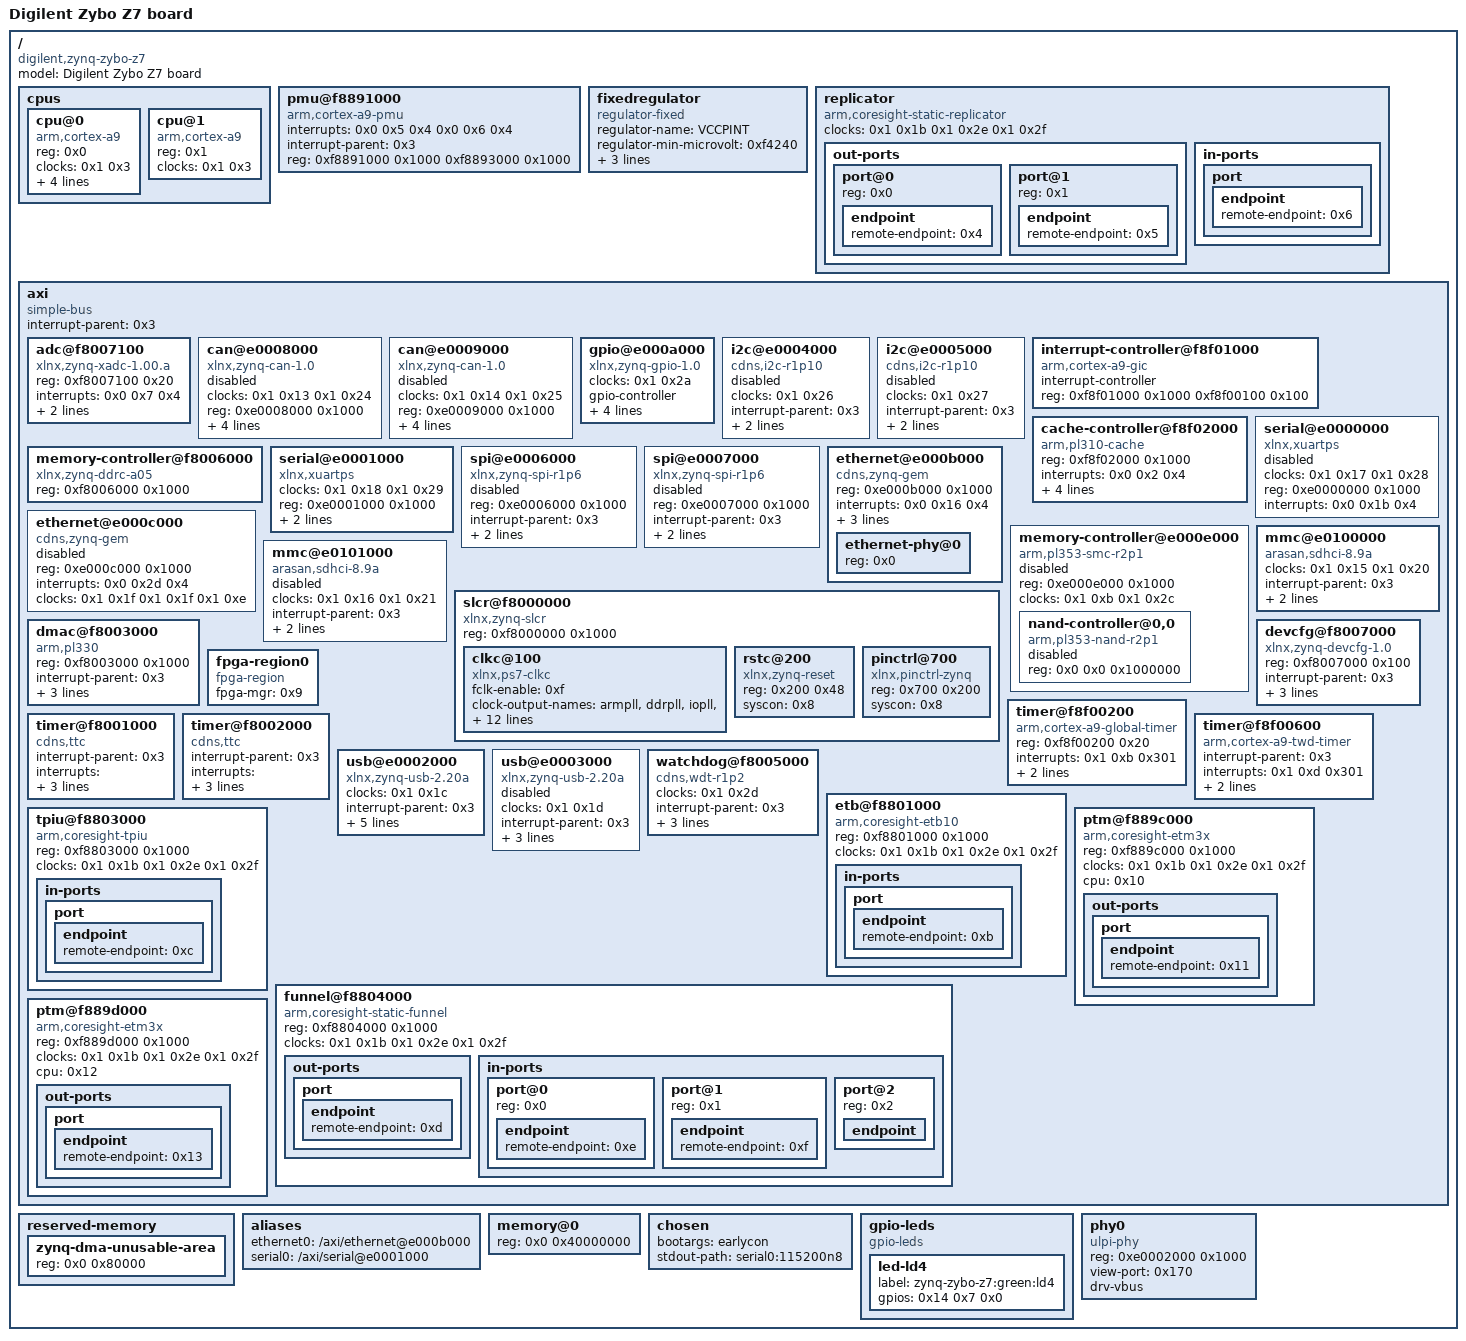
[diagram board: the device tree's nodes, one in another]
/dts-v1/;

/ {
	#address-cells = <0x1>;
	#size-cells = <0x1>;
	compatible = "digilent,zynq-zybo-z7", "xlnx,zynq-7000";
	model = "Digilent Zybo Z7 board";

	cpus {
		#address-cells = <0x1>;
		#size-cells = <0x0>;

		cpu@0 {
			compatible = "arm,cortex-a9";
			device_type = "cpu";
			reg = <0x0>;
			clocks = <0x1 0x3>;
			clock-latency = <0x3e8>;
			cpu0-supply = <0x2>;
			operating-points = <0xa2c2b 0xf4240 0x51616 0xf4240>;
			phandle = <0x10>;
		};

		cpu@1 {
			compatible = "arm,cortex-a9";
			device_type = "cpu";
			reg = <0x1>;
			clocks = <0x1 0x3>;
			phandle = <0x12>;
		};
	};

	pmu@f8891000 {
		compatible = "arm,cortex-a9-pmu";
		interrupts = <0x0 0x5 0x4 0x0 0x6 0x4>;
		interrupt-parent = <0x3>;
		reg = <0xf8891000 0x1000 0xf8893000 0x1000>;
	};

	fixedregulator {
		compatible = "regulator-fixed";
		regulator-name = "VCCPINT";
		regulator-min-microvolt = <0xf4240>;
		regulator-max-microvolt = <0xf4240>;
		regulator-boot-on;
		regulator-always-on;
		phandle = <0x2>;
	};

	replicator {
		compatible = "arm,coresight-static-replicator";
		clocks = <0x1 0x1b 0x1 0x2e 0x1 0x2f>;
		clock-names = "apb_pclk", "dbg_trc", "dbg_apb";

		out-ports {
			#address-cells = <0x1>;
			#size-cells = <0x0>;

			port@0 {
				reg = <0x0>;

				endpoint {
					remote-endpoint = <0x4>;
					phandle = <0xc>;
				};
			};

			port@1 {
				reg = <0x1>;

				endpoint {
					remote-endpoint = <0x5>;
					phandle = <0xb>;
				};
			};
		};

		in-ports {

			port {

				endpoint {
					remote-endpoint = <0x6>;
					phandle = <0xd>;
				};
			};
		};
	};

	axi {
		compatible = "simple-bus";
		#address-cells = <0x1>;
		#size-cells = <0x1>;
		interrupt-parent = <0x3>;
		ranges;
		phandle = <0x15>;

		adc@f8007100 {
			compatible = "xlnx,zynq-xadc-1.00.a";
			reg = <0xf8007100 0x20>;
			interrupts = <0x0 0x7 0x4>;
			interrupt-parent = <0x3>;
			clocks = <0x1 0xc>;
			phandle = <0x16>;
		};

		can@e0008000 {
			compatible = "xlnx,zynq-can-1.0";
			status = "disabled";
			clocks = <0x1 0x13 0x1 0x24>;
			clock-names = "can_clk", "pclk";
			reg = <0xe0008000 0x1000>;
			interrupts = <0x0 0x1c 0x4>;
			interrupt-parent = <0x3>;
			tx-fifo-depth = <0x40>;
			rx-fifo-depth = <0x40>;
			phandle = <0x17>;
		};

		can@e0009000 {
			compatible = "xlnx,zynq-can-1.0";
			status = "disabled";
			clocks = <0x1 0x14 0x1 0x25>;
			clock-names = "can_clk", "pclk";
			reg = <0xe0009000 0x1000>;
			interrupts = <0x0 0x33 0x4>;
			interrupt-parent = <0x3>;
			tx-fifo-depth = <0x40>;
			rx-fifo-depth = <0x40>;
			phandle = <0x18>;
		};

		gpio@e000a000 {
			compatible = "xlnx,zynq-gpio-1.0";
			#gpio-cells = <0x2>;
			clocks = <0x1 0x2a>;
			gpio-controller;
			interrupt-controller;
			#interrupt-cells = <0x2>;
			interrupt-parent = <0x3>;
			interrupts = <0x0 0x14 0x4>;
			reg = <0xe000a000 0x1000>;
			phandle = <0x14>;
		};

		i2c@e0004000 {
			compatible = "cdns,i2c-r1p10";
			status = "disabled";
			clocks = <0x1 0x26>;
			interrupt-parent = <0x3>;
			interrupts = <0x0 0x19 0x4>;
			reg = <0xe0004000 0x1000>;
			#address-cells = <0x1>;
			#size-cells = <0x0>;
			phandle = <0x19>;
		};

		i2c@e0005000 {
			compatible = "cdns,i2c-r1p10";
			status = "disabled";
			clocks = <0x1 0x27>;
			interrupt-parent = <0x3>;
			interrupts = <0x0 0x30 0x4>;
			reg = <0xe0005000 0x1000>;
			#address-cells = <0x1>;
			#size-cells = <0x0>;
			phandle = <0x1a>;
		};

		interrupt-controller@f8f01000 {
			compatible = "arm,cortex-a9-gic";
			#interrupt-cells = <0x3>;
			interrupt-controller;
			reg = <0xf8f01000 0x1000 0xf8f00100 0x100>;
			phandle = <0x3>;
		};

		cache-controller@f8f02000 {
			compatible = "arm,pl310-cache";
			reg = <0xf8f02000 0x1000>;
			interrupts = <0x0 0x2 0x4>;
			arm,data-latency = <0x3 0x2 0x2>;
			arm,tag-latency = <0x2 0x2 0x2>;
			cache-unified;
			cache-level = <0x2>;
			phandle = <0x1b>;
		};

		memory-controller@f8006000 {
			compatible = "xlnx,zynq-ddrc-a05";
			reg = <0xf8006000 0x1000>;
			phandle = <0x1c>;
		};

		serial@e0000000 {
			compatible = "xlnx,xuartps", "cdns,uart-r1p8";
			status = "disabled";
			clocks = <0x1 0x17 0x1 0x28>;
			clock-names = "uart_clk", "pclk";
			reg = <0xe0000000 0x1000>;
			interrupts = <0x0 0x1b 0x4>;
			phandle = <0x1d>;
		};

		serial@e0001000 {
			compatible = "xlnx,xuartps", "cdns,uart-r1p8";
			status = "okay";
			clocks = <0x1 0x18 0x1 0x29>;
			clock-names = "uart_clk", "pclk";
			reg = <0xe0001000 0x1000>;
			interrupts = <0x0 0x32 0x4>;
			clock-frequency = <0x1c2000>;
			phandle = <0x1e>;
		};

		spi@e0006000 {
			compatible = "xlnx,zynq-spi-r1p6";
			reg = <0xe0006000 0x1000>;
			status = "disabled";
			interrupt-parent = <0x3>;
			interrupts = <0x0 0x1a 0x4>;
			clocks = <0x1 0x19 0x1 0x22>;
			clock-names = "ref_clk", "pclk";
			#address-cells = <0x1>;
			#size-cells = <0x0>;
			phandle = <0x1f>;
		};

		spi@e0007000 {
			compatible = "xlnx,zynq-spi-r1p6";
			reg = <0xe0007000 0x1000>;
			status = "disabled";
			interrupt-parent = <0x3>;
			interrupts = <0x0 0x31 0x4>;
			clocks = <0x1 0x1a 0x1 0x23>;
			clock-names = "ref_clk", "pclk";
			#address-cells = <0x1>;
			#size-cells = <0x0>;
			phandle = <0x20>;
		};

		ethernet@e000b000 {
			compatible = "cdns,zynq-gem", "cdns,gem";
			reg = <0xe000b000 0x1000>;
			status = "okay";
			interrupts = <0x0 0x16 0x4>;
			clocks = <0x1 0x1e 0x1 0x1e 0x1 0xd>;
			clock-names = "pclk", "hclk", "tx_clk";
			#address-cells = <0x1>;
			#size-cells = <0x0>;
			phy-mode = "rgmii-id";
			phy-handle = <0x7>;
			phandle = <0x21>;

			ethernet-phy@0 {
				reg = <0x0>;
				device_type = "ethernet-phy";
				phandle = <0x7>;
			};
		};

		ethernet@e000c000 {
			compatible = "cdns,zynq-gem", "cdns,gem";
			reg = <0xe000c000 0x1000>;
			status = "disabled";
			interrupts = <0x0 0x2d 0x4>;
			clocks = <0x1 0x1f 0x1 0x1f 0x1 0xe>;
			clock-names = "pclk", "hclk", "tx_clk";
			#address-cells = <0x1>;
			#size-cells = <0x0>;
			phandle = <0x22>;
		};

		memory-controller@e000e000 {
			compatible = "arm,pl353-smc-r2p1", "arm,primecell";
			reg = <0xe000e000 0x1000>;
			status = "disabled";
			clock-names = "memclk", "apb_pclk";
			clocks = <0x1 0xb 0x1 0x2c>;
			ranges = <0x0 0x0 0xe1000000 0x1000000 0x1 0x0 0xe2000000 0x2000000 0x2 0x0 0xe4000000 0x2000000>;
			#address-cells = <0x2>;
			#size-cells = <0x1>;
			phandle = <0x23>;

			nand-controller@0,0 {
				compatible = "arm,pl353-nand-r2p1";
				reg = <0x0 0x0 0x1000000>;
				status = "disabled";
				#address-cells = <0x1>;
				#size-cells = <0x0>;
				phandle = <0x24>;
			};
		};

		mmc@e0100000 {
			compatible = "arasan,sdhci-8.9a";
			status = "okay";
			clock-names = "clk_xin", "clk_ahb";
			clocks = <0x1 0x15 0x1 0x20>;
			interrupt-parent = <0x3>;
			interrupts = <0x0 0x18 0x4>;
			reg = <0xe0100000 0x1000>;
			phandle = <0x25>;
		};

		mmc@e0101000 {
			compatible = "arasan,sdhci-8.9a";
			status = "disabled";
			clock-names = "clk_xin", "clk_ahb";
			clocks = <0x1 0x16 0x1 0x21>;
			interrupt-parent = <0x3>;
			interrupts = <0x0 0x2f 0x4>;
			reg = <0xe0101000 0x1000>;
			phandle = <0x26>;
		};

		slcr@f8000000 {
			#address-cells = <0x1>;
			#size-cells = <0x1>;
			compatible = "xlnx,zynq-slcr", "syscon", "simple-mfd";
			reg = <0xf8000000 0x1000>;
			ranges;
			phandle = <0x8>;

			clkc@100 {
				#clock-cells = <0x1>;
				compatible = "xlnx,ps7-clkc";
				fclk-enable = <0xf>;
				clock-output-names = "armpll", "ddrpll", "iopll", "cpu_6or4x", "cpu_3or2x", "cpu_2x", "cpu_1x", "ddr2x", "ddr3x", "dci", "lqspi", "smc", "pcap", "gem0", "gem1", "fclk0", "fclk1", "fclk2", "fclk3", "can0", "can1", "sdio0", "sdio1", "uart0", "uart1", "spi0", "spi1", "dma", "usb0_aper", "usb1_aper", "gem0_aper", "gem1_aper", "sdio0_aper", "sdio1_aper", "spi0_aper", "spi1_aper", "can0_aper", "can1_aper", "i2c0_aper", "i2c1_aper", "uart0_aper", "uart1_aper", "gpio_aper", "lqspi_aper", "smc_aper", "swdt", "dbg_trc", "dbg_apb";
				reg = <0x100 0x100>;
				ps-clk-frequency = <0x1fca055>;
				phandle = <0x1>;
			};

			rstc@200 {
				compatible = "xlnx,zynq-reset";
				reg = <0x200 0x48>;
				#reset-cells = <0x1>;
				syscon = <0x8>;
				phandle = <0x27>;
			};

			pinctrl@700 {
				compatible = "xlnx,pinctrl-zynq";
				reg = <0x700 0x200>;
				syscon = <0x8>;
				phandle = <0x28>;
			};
		};

		dmac@f8003000 {
			compatible = "arm,pl330", "arm,primecell";
			reg = <0xf8003000 0x1000>;
			interrupt-parent = <0x3>;
			interrupt-names = "abort", "dma0", "dma1", "dma2", "dma3", "dma4", "dma5", "dma6", "dma7";
			interrupts = <0x0 0xd 0x4 0x0 0xe 0x4 0x0 0xf 0x4 0x0 0x10 0x4 0x0 0x11 0x4 0x0 0x28 0x4 0x0 0x29 0x4 0x0 0x2a 0x4 0x0 0x2b 0x4>;
			#dma-cells = <0x1>;
			clocks = <0x1 0x1b>;
			clock-names = "apb_pclk";
			phandle = <0x29>;
		};

		devcfg@f8007000 {
			compatible = "xlnx,zynq-devcfg-1.0";
			reg = <0xf8007000 0x100>;
			interrupt-parent = <0x3>;
			interrupts = <0x0 0x8 0x4>;
			clocks = <0x1 0xc>;
			clock-names = "ref_clk";
			syscon = <0x8>;
			phandle = <0x9>;
		};

		fpga-region0 {
			compatible = "fpga-region";
			fpga-mgr = <0x9>;
			#address-cells = <0x1>;
			#size-cells = <0x1>;
			ranges;
			phandle = <0x2a>;
		};

		timer@f8f00200 {
			compatible = "arm,cortex-a9-global-timer";
			reg = <0xf8f00200 0x20>;
			interrupts = <0x1 0xb 0x301>;
			interrupt-parent = <0x3>;
			clocks = <0x1 0x4>;
			phandle = <0x2b>;
		};

		timer@f8001000 {
			interrupt-parent = <0x3>;
			interrupts = <0x0 0xa 0x4 0x0 0xb 0x4 0x0 0xc 0x4>;
			compatible = "cdns,ttc";
			clocks = <0x1 0x6>;
			reg = <0xf8001000 0x1000>;
			phandle = <0x2c>;
		};

		timer@f8002000 {
			interrupt-parent = <0x3>;
			interrupts = <0x0 0x25 0x4 0x0 0x26 0x4 0x0 0x27 0x4>;
			compatible = "cdns,ttc";
			clocks = <0x1 0x6>;
			reg = <0xf8002000 0x1000>;
			phandle = <0x2d>;
		};

		timer@f8f00600 {
			interrupt-parent = <0x3>;
			interrupts = <0x1 0xd 0x301>;
			compatible = "arm,cortex-a9-twd-timer";
			reg = <0xf8f00600 0x20>;
			clocks = <0x1 0x4>;
			phandle = <0x2e>;
		};

		usb@e0002000 {
			compatible = "xlnx,zynq-usb-2.20a", "chipidea,usb2";
			status = "okay";
			clocks = <0x1 0x1c>;
			interrupt-parent = <0x3>;
			interrupts = <0x0 0x15 0x4>;
			reg = <0xe0002000 0x1000>;
			phy_type = "ulpi";
			dr_mode = "host";
			usb-phy = <0xa>;
			phandle = <0x2f>;
		};

		usb@e0003000 {
			compatible = "xlnx,zynq-usb-2.20a", "chipidea,usb2";
			status = "disabled";
			clocks = <0x1 0x1d>;
			interrupt-parent = <0x3>;
			interrupts = <0x0 0x2c 0x4>;
			reg = <0xe0003000 0x1000>;
			phy_type = "ulpi";
			phandle = <0x30>;
		};

		watchdog@f8005000 {
			clocks = <0x1 0x2d>;
			compatible = "cdns,wdt-r1p2";
			interrupt-parent = <0x3>;
			interrupts = <0x0 0x9 0x1>;
			reg = <0xf8005000 0x1000>;
			timeout-sec = <0xa>;
			phandle = <0x31>;
		};

		etb@f8801000 {
			compatible = "arm,coresight-etb10", "arm,primecell";
			reg = <0xf8801000 0x1000>;
			clocks = <0x1 0x1b 0x1 0x2e 0x1 0x2f>;
			clock-names = "apb_pclk", "dbg_trc", "dbg_apb";

			in-ports {

				port {

					endpoint {
						remote-endpoint = <0xb>;
						phandle = <0x5>;
					};
				};
			};
		};

		tpiu@f8803000 {
			compatible = "arm,coresight-tpiu", "arm,primecell";
			reg = <0xf8803000 0x1000>;
			clocks = <0x1 0x1b 0x1 0x2e 0x1 0x2f>;
			clock-names = "apb_pclk", "dbg_trc", "dbg_apb";

			in-ports {

				port {

					endpoint {
						remote-endpoint = <0xc>;
						phandle = <0x4>;
					};
				};
			};
		};

		funnel@f8804000 {
			compatible = "arm,coresight-static-funnel", "arm,primecell";
			reg = <0xf8804000 0x1000>;
			clocks = <0x1 0x1b 0x1 0x2e 0x1 0x2f>;
			clock-names = "apb_pclk", "dbg_trc", "dbg_apb";

			out-ports {

				port {

					endpoint {
						remote-endpoint = <0xd>;
						phandle = <0x6>;
					};
				};
			};

			in-ports {
				#address-cells = <0x1>;
				#size-cells = <0x0>;

				port@0 {
					reg = <0x0>;

					endpoint {
						remote-endpoint = <0xe>;
						phandle = <0x11>;
					};
				};

				port@1 {
					reg = <0x1>;

					endpoint {
						remote-endpoint = <0xf>;
						phandle = <0x13>;
					};
				};

				port@2 {
					reg = <0x2>;

					endpoint {
						phandle = <0x32>;
					};
				};
			};
		};

		ptm@f889c000 {
			compatible = "arm,coresight-etm3x", "arm,primecell";
			reg = <0xf889c000 0x1000>;
			clocks = <0x1 0x1b 0x1 0x2e 0x1 0x2f>;
			clock-names = "apb_pclk", "dbg_trc", "dbg_apb";
			cpu = <0x10>;

			out-ports {

				port {

					endpoint {
						remote-endpoint = <0x11>;
						phandle = <0xe>;
					};
				};
			};
		};

		ptm@f889d000 {
			compatible = "arm,coresight-etm3x", "arm,primecell";
			reg = <0xf889d000 0x1000>;
			clocks = <0x1 0x1b 0x1 0x2e 0x1 0x2f>;
			clock-names = "apb_pclk", "dbg_trc", "dbg_apb";
			cpu = <0x12>;

			out-ports {

				port {

					endpoint {
						remote-endpoint = <0x13>;
						phandle = <0xf>;
					};
				};
			};
		};
	};

	reserved-memory {
		#address-cells = <0x1>;
		#size-cells = <0x1>;
		ranges;

		zynq-dma-unusable-area {
			reg = <0x0 0x80000>;
		};
	};

	aliases {
		ethernet0 = "/axi/ethernet@e000b000";
		serial0 = "/axi/serial@e0001000";
	};

	memory@0 {
		device_type = "memory";
		reg = <0x0 0x40000000>;
	};

	chosen {
		bootargs = "earlycon";
		stdout-path = "serial0:115200n8";
	};

	gpio-leds {
		compatible = "gpio-leds";

		led-ld4 {
			label = "zynq-zybo-z7:green:ld4";
			gpios = <0x14 0x7 0x0>;
		};
	};

	phy0 {
		compatible = "ulpi-phy";
		#phy-cells = <0x0>;
		reg = <0xe0002000 0x1000>;
		view-port = <0x170>;
		drv-vbus;
		phandle = <0xa>;
	};

	__symbols__ {
		cpu0 = "/cpus/cpu@0";
		cpu1 = "/cpus/cpu@1";
		regulator_vccpint = "/fixedregulator";
		replicator_out_port0 = "/replicator/out-ports/port@0/endpoint";
		replicator_out_port1 = "/replicator/out-ports/port@1/endpoint";
		replicator_in_port0 = "/replicator/in-ports/port/endpoint";
		amba = "/axi";
		adc = "/axi/adc@f8007100";
		can0 = "/axi/can@e0008000";
		can1 = "/axi/can@e0009000";
		gpio0 = "/axi/gpio@e000a000";
		i2c0 = "/axi/i2c@e0004000";
		i2c1 = "/axi/i2c@e0005000";
		intc = "/axi/interrupt-controller@f8f01000";
		L2 = "/axi/cache-controller@f8f02000";
		mc = "/axi/memory-controller@f8006000";
		uart0 = "/axi/serial@e0000000";
		uart1 = "/axi/serial@e0001000";
		spi0 = "/axi/spi@e0006000";
		spi1 = "/axi/spi@e0007000";
		gem0 = "/axi/ethernet@e000b000";
		ethernet_phy = "/axi/ethernet@e000b000/ethernet-phy@0";
		gem1 = "/axi/ethernet@e000c000";
		smcc = "/axi/memory-controller@e000e000";
		nfc0 = "/axi/memory-controller@e000e000/nand-controller@0,0";
		sdhci0 = "/axi/mmc@e0100000";
		sdhci1 = "/axi/mmc@e0101000";
		slcr = "/axi/slcr@f8000000";
		clkc = "/axi/slcr@f8000000/clkc@100";
		rstc = "/axi/slcr@f8000000/rstc@200";
		pinctrl0 = "/axi/slcr@f8000000/pinctrl@700";
		dmac_s = "/axi/dmac@f8003000";
		devcfg = "/axi/devcfg@f8007000";
		fpga_region0 = "/axi/fpga-region0";
		global_timer = "/axi/timer@f8f00200";
		ttc0 = "/axi/timer@f8001000";
		ttc1 = "/axi/timer@f8002000";
		scutimer = "/axi/timer@f8f00600";
		usb0 = "/axi/usb@e0002000";
		usb1 = "/axi/usb@e0003000";
		watchdog0 = "/axi/watchdog@f8005000";
		etb_in_port = "/axi/etb@f8801000/in-ports/port/endpoint";
		tpiu_in_port = "/axi/tpiu@f8803000/in-ports/port/endpoint";
		funnel_out_port = "/axi/funnel@f8804000/out-ports/port/endpoint";
		funnel0_in_port0 = "/axi/funnel@f8804000/in-ports/port@0/endpoint";
		funnel0_in_port1 = "/axi/funnel@f8804000/in-ports/port@1/endpoint";
		funnel0_in_port2 = "/axi/funnel@f8804000/in-ports/port@2/endpoint";
		ptm0_out_port = "/axi/ptm@f889c000/out-ports/port/endpoint";
		ptm1_out_port = "/axi/ptm@f889d000/out-ports/port/endpoint";
		usb_phy0 = "/phy0";
	};
};
